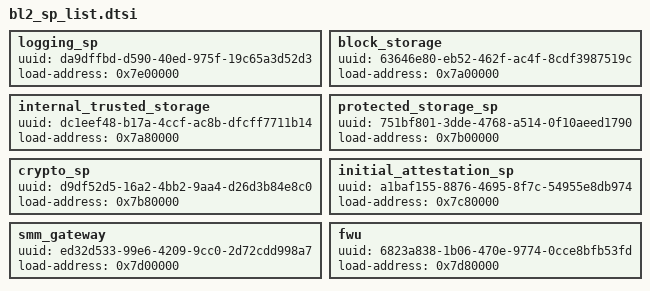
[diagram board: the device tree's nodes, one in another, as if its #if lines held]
/* SPDX-License-Identifier: BSD-3-Clause */
/*
 * Copyright (c) 2022-2023, Arm Limited. All rights reserved.
 */

#if !SPMC_TESTS
#if TS_LOGGING_SP
logging_sp {
	uuid = "da9dffbd-d590-40ed-975f-19c65a3d52d3";
	load-address = <0x7e00000>;
};
#endif /* TS_LOGGING_SP */

block_storage {
	uuid = "63646e80-eb52-462f-ac4f-8cdf3987519c";
	load-address = <0x7a00000>;
};

internal_trusted_storage {
	uuid = "dc1eef48-b17a-4ccf-ac8b-dfcff7711b14";
	load-address = <0x7a80000>;
};

protected_storage_sp {
	uuid = "751bf801-3dde-4768-a514-0f10aeed1790";
	load-address = <0x7b00000>;
};

crypto_sp {
	uuid = "d9df52d5-16a2-4bb2-9aa4-d26d3b84e8c0";
	load-address = <0x7b80000>;
};

#if MEASURED_BOOT
initial_attestation_sp {
	uuid = "a1baf155-8876-4695-8f7c-54955e8db974";
	load-address = <0x7c80000>;
};
#endif /* MEASURED_BOOT */

#if TS_SMM_GATEWAY
smm_gateway {
	uuid = "ed32d533-99e6-4209-9cc0-2d72cdd998a7";
	load-address = <0x7d00000>;
};
#endif /* TS_SMM_GATEWAY */

#if TS_FW_UPDATE
fwu {
	uuid = "6823a838-1b06-470e-9774-0cce8bfb53fd";
	load-address = <0x7d80000>;
};
#endif /* TS_FW_UPDATE */

#else /* SPMC_TESTS */

test_sp1 {
	uuid = "5c9edbc3-7b3a-4367-9f83-7c191ae86a37";
	load-address = <0x7a00000>;
};

test_sp2 {
	uuid = "7817164c-c40c-4d1a-867a-9bb2278cf41a";
	load-address = <0x7a20000>;
};

test_sp3 {
	uuid = "23eb0100-e32a-4497-9052-2f11e584afa6";
	load-address = <0x7a40000>;
};

test_sp4 {
	uuid = "423762ed-7772-406f-99d8-0c27da0abbf8";
	load-address = <0x7a80000>;
};

#endif /* SPMC_TESTS */
